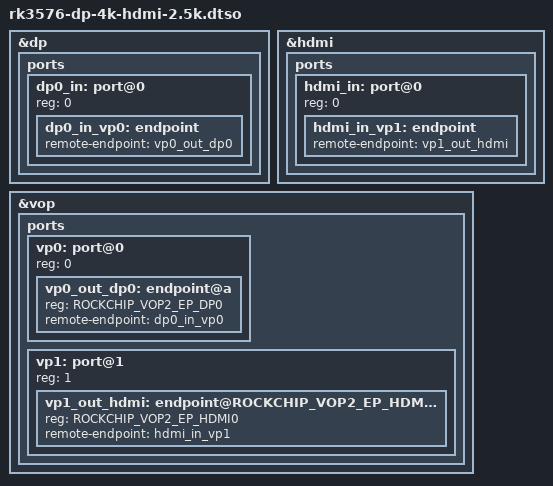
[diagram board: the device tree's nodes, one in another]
// SPDX-License-Identifier: (GPL-2.0+ OR MIT)
/*
 * DT-overlay to switch from the default HDMI 4k and DP 2.5k mode to DP 4K and
 * HDMI 2.5k mode. Should be applicable for any boards having both HDMI and DP
 */

#include <dt-bindings/soc/rockchip,vop2.h>

/dts-v1/;
/plugin/;

&dp {
	status = "okay";

	ports {
		#address-cells = <1>;
		#size-cells = <0>;

		dp0_in: port@0 {
			reg = <0>;
		};
	};
};

&dp0_in {
	dp0_in_vp0: endpoint {
		remote-endpoint = <&vp0_out_dp0>;
	};
};

&hdmi {
	status = "okay";

	ports {
		#address-cells = <1>;
		#size-cells = <0>;

		hdmi_in: port@0 {
			reg = <0>;
		};
	};
};

&hdmi_in {
	hdmi_in_vp1: endpoint {
		remote-endpoint = <&vp1_out_hdmi>;
	};
};

&vop {
	status = "okay";

	ports {
		#address-cells = <1>;
		#size-cells = <0>;

		vp0: port@0 {
			#address-cells = <1>;
			#size-cells = <0>;
			reg = <0>;
		};

		vp1: port@1 {
			#address-cells = <1>;
			#size-cells = <0>;
			reg = <1>;
		};
	};
};

&vp0 {
	vp0_out_dp0: endpoint@a {
		reg = <ROCKCHIP_VOP2_EP_DP0>;
		remote-endpoint = <&dp0_in_vp0>;
	};
};

&vp1 {
	vp1_out_hdmi: endpoint@ROCKCHIP_VOP2_EP_HDMI0 {
		reg = <ROCKCHIP_VOP2_EP_HDMI0>;
		remote-endpoint = <&hdmi_in_vp1>;
	};
};
